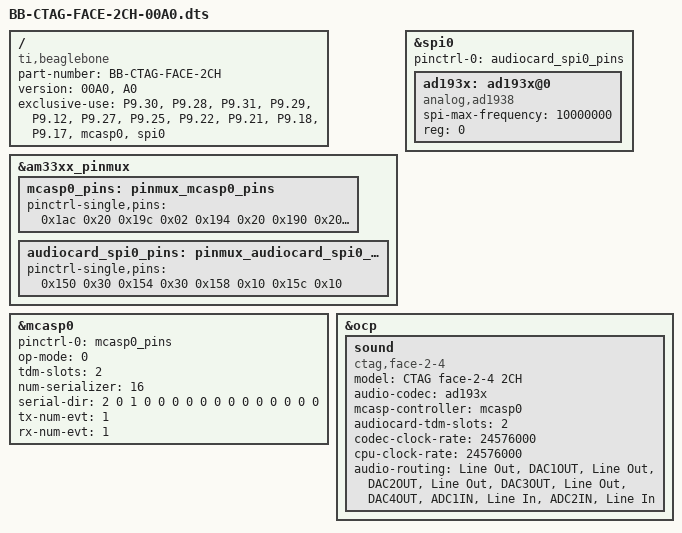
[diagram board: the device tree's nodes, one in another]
/*
 * Device Tree Overlay for CTAG face2|4 multichannel soundcard - 2 audio channels
 *
 * Author: Henrik Langer <henni19790@googlemail.com>
 *
 * This program is free software; you can redistribute it and/or modify
 * it under the terms of the GNU General Public License version 3 as
 * published by the Free Software Foundation.
 */
/dts-v1/;
/plugin/;

/ {
	compatible = "ti,beaglebone", "ti,beaglebone-black", "ti,beaglebone-green";

	/* identification */
	part-number = "BB-CTAG-FACE-2CH";
	version = "00A0", "A0";

	/* state the resources this cape uses */
	exclusive-use =
		/* audio */
		"P9.30",	/* mcasp0_axr0 		audio in */
		"P9.28",	/* mcasp0_axr2 		audio out */
		"P9.31",	/* mcasp0_ahclkx	transmit bitclock */
		"P9.29",	/* mcasp0_fsx 		transmit frameclock */
		"P9.12",	/* mcasp0_aclkr		receive bitclock */
		"P9.27",	/* mcasp0_fsr		receive frameclock */
		"P9.25",	/* mcasp0_ahclkx 	masterclock */
		/* spi */
		"P9.22",	/* spi0_sclk */
		"P9.21",	/* spi0_d0 */
		"P9.18",	/* spi0_d1 */
		"P9.17",	/* spi0_cs0 */
		/* the hardware ip uses */
		"mcasp0", "spi0";

	fragment@0 {
		target = <&am33xx_pinmux>;
		__overlay__ {
			mcasp0_pins: pinmux_mcasp0_pins {
				pinctrl-single,pins = <
					0x1ac 0x20		/* mcasp0_ahclkx,	MODE0 | INPUT_PULLDOWN | P9_25 */
					0x19c 0x02		/* mcasp0_axr2,		MODE2 | OUTPUT_PULLDOWN | P9_28 */
					0x194 0x20		/* mcasp0_fsx, 		MODE0 | INPUT_PULLDOWN | P9_29 */
					0x190 0x20		/* mcasp0_aclkx, 	MODE0 | INPUT_PULLDOWN | P9_31 */
					0x1a4 0x20		/* mcasp0_fsr,		MODE0 | INPUT_PULLDOWN | P9_27 */
					0x078 0x26		/* mcasp0_aclkr,	MODE6 | INPUT_PULLDOWN | P9_12 */
					0x198 0x20		/* mcasp0_axr0, 	MODE0 | INPUT_PULLDOWN | P9_30 */
				>;
			};

			audiocard_spi0_pins: pinmux_audiocard_spi0_pins { 
				pinctrl-single,pins = <
					0x150 0x30		/* spi0_sclk, 	MODE0 | INPUT_PULLUP | SPI0_SCLK P9_22 */
                    0x154 0x30		/* spi0_d0, 	MODE0 | INPUT_PULLUP | SPI0_MISO P9_21 */
                    0x158 0x10		/* spi0_d1, 	MODE0 | OUTPUT_PULLUP | SPI0_MOSI P9_18 */
                    0x15c 0x10		/* spi0_cs0, 	MODE0 | OUTPUT_PULLUP | SPI0_CS0 P9_17 */
				>;
			};
		};
	};

	fragment@1 {
		target = <&spi0>;
		__overlay__ {
			pinctrl-names = "default";
			pinctrl-0 = <&audiocard_spi0_pins>;
			status = "okay";

			/* avoid dtc warnings */
			#address-cells = <1>;
			#size-cells = <0>;

			ad193x: ad193x@0{
				spi-max-frequency = <10000000>;
				reg = <0>;
				compatible = "analog,ad1938";
			};
		};
	};

	fragment@2 {
		target = <&mcasp0>;
		__overlay__ {
			pinctrl-names = "default";
			pinctrl-0 = <&mcasp0_pins>;

			status = "okay";

			op-mode = <0>;	/* MCASP_IIS_MODE */
			tdm-slots = <2>;
			num-serializer = <16>;
			serial-dir = <  /* 0: INACTIVE, 1: TX, 2: RX */
				2 0 1 0
				0 0 0 0
				0 0 0 0
				0 0 0 0
			>;
			tx-num-evt = <1>;
			rx-num-evt = <1>;
		};
	};

	fragment@3 {
		target = <&ocp>;
		__overlay__ {

			sound {
				compatible = "ctag,face-2-4";
				model = "CTAG face-2-4 2CH";
				audio-codec = <&ad193x>;
				mcasp-controller = <&mcasp0>;
				audiocard-tdm-slots = <2>;
				codec-clock-rate = <24576000>;
				cpu-clock-rate = <24576000>;
				audio-routing =
					"Line Out",             "DAC1OUT",
					"Line Out",             "DAC2OUT",
					"Line Out",             "DAC3OUT",
					"Line Out",             "DAC4OUT",
					"ADC1IN",               "Line In",
					"ADC2IN",               "Line In";
			};
		};
	};
};
